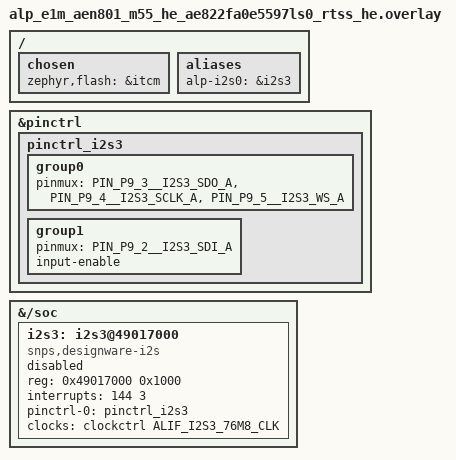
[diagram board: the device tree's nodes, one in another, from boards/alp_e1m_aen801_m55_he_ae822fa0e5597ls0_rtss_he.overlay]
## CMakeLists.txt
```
# SPDX-License-Identifier: Apache-2.0
cmake_minimum_required(VERSION 3.20)
find_package(Zephyr REQUIRED HINTS $ENV{ZEPHYR_BASE})
project(aen_i2s_amp_alif LANGUAGES C)
target_sources(app PRIVATE src/main.c)
```

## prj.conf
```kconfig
# SPDX-License-Identifier: Apache-2.0
#
# Bench RAM-run config for the E1M-AEN801 (M55-HE).

# Tier-1.5 / Tier-2 driver Kconfigs (incl. CONFIG_I2S_DW) are gated under ALP_SDK.
CONFIG_ALP_SDK=y

# I2S subsystem + the vendored Alif DesignWare I2S driver. CONFIG_I2S_DW is
# `default y` once the i2s0 node is enabled (DT_HAS_SNPS_DESIGNWARE_I2S_ENABLED)
# and it `select`s PINCTRL itself -- we only turn on the I2S API here.
CONFIG_I2S=y

# Tone blocks come from a k_mem_slab + the kernel heap.
CONFIG_HEAP_MEM_POOL_SIZE=16384
CONFIG_MAIN_STACK_SIZE=4096

# FIFO is fed by the CPU from a plain buffer -- keep the data path coherent on
# this M55 bench by disabling the D-cache (matches the other E8 bench apps).
CONFIG_DCACHE=n

# Console: Alp UART console -- E1M edge UART0 (Alif UART5, P3_4/P3_5, 115200
# 8N1, NS16550), the E1M-AEN801 carrier console. The board _defconfig already
# selects it; we set it explicitly here so the example is self-describing.
CONFIG_SERIAL=y
CONFIG_CONSOLE=y
CONFIG_UART_CONSOLE=y
CONFIG_UART_INTERRUPT_DRIVEN=y
# Serial-less bench? Comment the four lines above and uncomment these to read
# 'ram_console_buf' over SWD instead:
# CONFIG_RAM_CONSOLE=y
# CONFIG_RAM_CONSOLE_BUFFER_SIZE=2048
# CONFIG_UART_CONSOLE=n
CONFIG_PRINTK=y
```

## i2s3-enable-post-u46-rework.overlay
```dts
/*
 * Copyright (c) 2026 Alp Lab AB
 * SPDX-License-Identifier: Apache-2.0
 *
 * The single documented switch that turns i2s3 back on -- see the SAFETY
 * note in boards/alp_e1m_aen801_m55_he_ae822fa0e5597ls0_rtss_he.overlay for
 * why the node ships "disabled" by default on EVK rev 2626-R2 (U46 has no
 * Hi-Z state, and I2S0_SDO/SCLK/WS on P9_3/4/5 run through it backwards).
 *
 * Apply ONLY once U46 is a 3257-type bus switch -- removes the
 * contention hazard regardless of which rail powers it; this app
 * never drives EN or SEL and does not test the amps. Amp audibility
 * is separate: on E1M-AEN803 serial 2026W36-0002 (2026-09-15), VCC was moved to +3V3
 * between a silent run and an audible run, not established as the
 * only difference; a switch rated for 1.8 V VCC is the untested
 * alternative (see include/alp/boards/alp_e1m_evk.h's I2S mux block):
 *
 *   west build -b alp_e1m_aen801_m55_he/ae822fa0e5597ls0/rtss_he \
 *       examples/aen/aen-i2s-amp-alif -- \
 *       -DEXTRA_DTC_OVERLAY_FILE=i2s3-enable-post-u46-rework.overlay
 *   (relative to this app's own source dir, examples/aen/aen-i2s-amp-alif)
 */

&i2s3 {
	status = "okay";
};
```

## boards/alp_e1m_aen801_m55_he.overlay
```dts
/*
 * Copyright (c) 2026 Alp Lab AB
 * SPDX-License-Identifier: Apache-2.0
 *
 * I2S0 audio-out overlay for the E1M-AEN801 (E8, M55-HE).
 *
 * i2s0@49014000 (compatible snps,designware-i2s, IRQ 141, clock ALIF_I2S0_76M8_CLK)
 * is transcribed from the Apache-2.0 zephyr_alif fork (dts/arm/alif/ensemble/
 * common/e1.dtsi) -- the alp-sdk E8 SoC dtsi doesn't carry it, so it is enabled
 * here.  Driver: drivers/i2s/i2s_dw.c (vendored Tier-2, CONFIG_I2S_DW).
 *
 * PADS -- TBD, see [[project_pending_hw_configs]] / [[project_som_pad_map_lives_in_alp_sdk]]:
 * the SoC offers I2S0 on TWO pad options (header ensemble-e4-e6-e8-pinctrl.h):
 *   A: P1_6 SDI / P1_7 SDO / P3_0 SCLK / P3_1 WS
 *   B: P4_1 SDI / P4_2 SDO / P4_3 SCLK / P4_4 WS
 * Which one the E1M-AEN801 SoM routes to the I2S0 edge (and on to the EVK 74LVC157
 * mux -> TAS2563 amps) is NOT yet declared in metadata/e1m_modules/E1M-AEN801.yaml.
 * This overlay uses the **A** option as a documented default; CONFIRM against the
 * SoM schematic before trusting amp output.  Re-point to the B group if the SoM
 * routes I2S0_B.
 */
#include <zephyr/dt-bindings/pinctrl/alif-ensemble-pinctrl.h>
#include <zephyr/dt-bindings/clock/alif-ensemble-clocks-ext.h>

/ {
	chosen {
		zephyr,flash = &itcm; /* bench RAM/SES-load; path-ref form */
		/delete-property/ zephyr,code-partition;
	};
	aliases {
		alp-i2s0 = &i2s0;
	};
};

&pinctrl {
	pinctrl_i2s0: pinctrl_i2s0 {
		/* TX path: SDO (data out) + SCLK + WS.  (read-enable, which the fork
		 * sets on the SDI input pad, is not in the upstream alif,pinctrl
		 * binding -- REN-off is the upstream default and SDI is unused for TX.) */
		group0 {
			pinmux = <PIN_P1_7__I2S0_SDO_A>, <PIN_P3_0__I2S0_SCLK_A>,
				 <PIN_P3_1__I2S0_WS_A>;
		};
	};
};

&{/soc} {
	i2s0: i2s0@49014000 {
		compatible = "snps,designware-i2s";
		reg = <0x49014000 0x1000>;
		interrupts = <141 3>;
		pinctrl-0 = <&pinctrl_i2s0>;
		pinctrl-names = "default";
		clocks = <&clockctrl ALIF_I2S0_76M8_CLK>;
		status = "okay";
	};
};
```

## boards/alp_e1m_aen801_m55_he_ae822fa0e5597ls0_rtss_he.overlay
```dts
/*
 * Copyright (c) 2026 Alp Lab AB
 * SPDX-License-Identifier: Apache-2.0
 *
 * Audio-I2S out overlay for the E1M-AEN801 (E8, M55-HE).
 *
 * The EVK audio I2S is the SoC's **i2s3** (i2s3@49017000) -- per the AUTHORITATIVE
 * SoM pinout metadata/e1m_modules/aen/from-alif.tsv, the board's "I2S0_*" audio
 * signals are wired to I2S3_*_A on P9_2..P9_5:
 *   I2S0_SDI -> I2S3_SDI_A = P9_2 | I2S0_SDO -> I2S3_SDO_A = P9_3
 *   I2S0_SCLK -> I2S3_SCLK_A = P9_4 | I2S0_WS -> I2S3_WS_A = P9_5
 * (NOT i2s0@49014000 -- that was the first cut's wrong instance.) The
 * snps,designware-i2s node + driver (drivers/i2s/i2s_dw.c, CONFIG_I2S_DW) are
 * transcribed from the fork; alias alp-i2s0 -> &i2s3 keeps the portable bus id.
 *
 * DISABLED BY DEFAULT on EVK rev 2626-R2: I2S0_SDO/SCLK/WS (P9_3/4/5) run
 * through U46, a 74LVC157 2:1 mux with NO high-impedance state -- with /E
 * high its Y outputs are forced LOW, not floated. Those Y outputs are wired
 * BACKWARDS for this direction (they drive the SoC's own I2S0_* pads, not
 * the amps or the M.2 slot), so the instant this i2s3 node's pinctrl muxes
 * P9_3/4/5 to the I2S3 alternate function and the controller drives them,
 * the SoC fights U46's forced-low outputs on the same pads -- whether or
 * not U46's /E is ever asserted. Disabling the whole node, not just
 * skipping the app's i2s_configure()/i2s_write() calls, is the point: a
 * disabled node gets no pinctrl-0 applied and no clock enabled at driver
 * init, so nothing drives P9_3/4/5 at all. To exercise this node once U46
 * is a 3257-type bus switch (removes this contention regardless of which
 * rail powers it -- this app never drives EN or SEL and does not test
 * the amps; amp audibility is a separate, stricter condition -- VCC was
 * moved to +3V3 between a silent run and an audible run on
 * E1M-AEN803 serial 2026W36-0002, not established as the only difference -- see
 * include/alp/boards/alp_e1m_evk.h's I2S mux block):
 * `-DEXTRA_DTC_OVERLAY_FILE=i2s3-enable-post-u46-rework.overlay`
 * (resolved relative to this app's own source dir, examples/aen/aen-i2s-amp-alif;
 * that file just sets `&i2s3 { status = "okay"; };`) -- the single documented
 * switch; nothing else in this app needs to change.
 */
#include <zephyr/dt-bindings/pinctrl/alif-ensemble-pinctrl.h>
#include <zephyr/dt-bindings/clock/alif-ensemble-clocks-ext.h>

/ {
	chosen {
		zephyr,flash = &itcm; /* bench RAM/SES-load; path-ref form */
		/delete-property/ zephyr,code-partition;
	};
	aliases {
		alp-i2s0 = &i2s3;
	};
};

&pinctrl {
	pinctrl_i2s3: pinctrl_i2s3 {
		/* TX: SDO + SCLK + WS, the I2S3_*_A route (P9_3/4/5). RX: SDI
		 * (P9_2, I2S3_SDI_A) -- U46's 4Y is the one leg of that mux wired
		 * the correct direction (unlike SDO/SCLK/WS, which contend with
		 * the SoC and are why this node ships disabled -- see the
		 * file-header SAFETY note), feeding the amps' SDOUT/IV-sense back
		 * to the SoC. input-enable sets the pad's REN bit so the input
		 * buffer actually samples; without it the mux alone is not
		 * sufficient to receive (REN defaults off). The original TX-only
		 * scope here was a deliberate choice, not a hazard -- that scope
		 * has since widened. Still inert on its own: this node ships
		 * "disabled" by default, so pinctrl-0 is not applied until
		 * i2s3-enable-post-u46-rework.overlay flips it "okay". */
		group0 {
			pinmux = <PIN_P9_3__I2S3_SDO_A>, <PIN_P9_4__I2S3_SCLK_A>,
				 <PIN_P9_5__I2S3_WS_A>;
		};
		group1 {
			pinmux = <PIN_P9_2__I2S3_SDI_A>;
			input-enable;
		};
	};
};

&{/soc} {
	i2s3: i2s3@49017000 {
		compatible = "snps,designware-i2s";
		reg = <0x49017000 0x1000>;
		interrupts = <144 3>;
		pinctrl-0 = <&pinctrl_i2s3>;
		pinctrl-names = "default";
		clocks = <&clockctrl ALIF_I2S3_76M8_CLK>;
		/* "disabled" by default -- see the file-header SAFETY note above.
		 * -DEXTRA_DTC_OVERLAY_FILE=i2s3-enable-post-u46-rework.overlay
		 * flips this back to "okay" once U46 is a 3257-type bus
		 * switch (any rail -- see the file-header note). */
		status = "disabled";
	};
};
```

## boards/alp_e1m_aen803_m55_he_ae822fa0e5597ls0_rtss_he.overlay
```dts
/*
 * Copyright (c) 2026 Alp Lab AB
 * SPDX-License-Identifier: Apache-2.0
 *
 * Audio-I2S out overlay for the E1M-AEN803 (E8, M55-HE).
 *
 * The EVK audio I2S is the SoC's **i2s3** (i2s3@49017000) -- per the AUTHORITATIVE
 * SoM pinout metadata/e1m_modules/aen/from-alif.tsv, the board's "I2S0_*" audio
 * signals are wired to I2S3_*_A on P9_2..P9_5:
 *   I2S0_SDI -> I2S3_SDI_A = P9_2 | I2S0_SDO -> I2S3_SDO_A = P9_3
 *   I2S0_SCLK -> I2S3_SCLK_A = P9_4 | I2S0_WS -> I2S3_WS_A = P9_5
 * (NOT i2s0@49014000 -- that was the first cut's wrong instance.) The
 * snps,designware-i2s node + driver (drivers/i2s/i2s_dw.c, CONFIG_I2S_DW) are
 * transcribed from the fork; alias alp-i2s0 -> &i2s3 keeps the portable bus id.
 *
 * DISABLED BY DEFAULT on EVK rev 2626-R2: I2S0_SDO/SCLK/WS (P9_3/4/5) run
 * through U46, a 74LVC157 2:1 mux with NO high-impedance state -- with /E
 * high its Y outputs are forced LOW, not floated. Those Y outputs are wired
 * BACKWARDS for this direction (they drive the SoC's own I2S0_* pads, not
 * the amps or the M.2 slot), so the instant this i2s3 node's pinctrl muxes
 * P9_3/4/5 to the I2S3 alternate function and the controller drives them,
 * the SoC fights U46's forced-low outputs on the same pads -- whether or
 * not U46's /E is ever asserted. Disabling the whole node, not just
 * skipping the app's i2s_configure()/i2s_write() calls, is the point: a
 * disabled node gets no pinctrl-0 applied and no clock enabled at driver
 * init, so nothing drives P9_3/4/5 at all. To exercise this node once U46
 * is a 3257-type bus switch (removes this contention regardless of which
 * rail powers it -- this app never drives EN or SEL and does not test
 * the amps; amp audibility is a separate, stricter condition -- VCC was
 * moved to +3V3 between a silent run and an audible run on
 * E1M-AEN803 serial 2026W36-0002, not established as the only difference -- see
 * include/alp/boards/alp_e1m_evk.h's I2S mux block):
 * `-DEXTRA_DTC_OVERLAY_FILE=i2s3-enable-post-u46-rework.overlay`
 * (resolved relative to this app's own source dir, examples/aen/aen-i2s-amp-alif;
 * that file just sets `&i2s3 { status = "okay"; };`) -- the single documented
 * switch; nothing else in this app needs to change.
 */
#include <zephyr/dt-bindings/pinctrl/alif-ensemble-pinctrl.h>
#include <zephyr/dt-bindings/clock/alif-ensemble-clocks-ext.h>

/ {
	chosen {
		zephyr,flash = &itcm; /* bench RAM/SES-load; path-ref form */
		/delete-property/ zephyr,code-partition;
	};
	aliases {
		alp-i2s0 = &i2s3;
	};
};

&pinctrl {
	pinctrl_i2s3: pinctrl_i2s3 {
		/* TX: SDO + SCLK + WS, the I2S3_*_A route (P9_3/4/5). RX: SDI
		 * (P9_2, I2S3_SDI_A) -- U46's 4Y is the one leg of that mux wired
		 * the correct direction (unlike SDO/SCLK/WS, which contend with
		 * the SoC and are why this node ships disabled -- see the
		 * file-header SAFETY note), feeding the amps' SDOUT/IV-sense back
		 * to the SoC. input-enable sets the pad's REN bit so the input
		 * buffer actually samples; without it the mux alone is not
		 * sufficient to receive (REN defaults off). The original TX-only
		 * scope here was a deliberate choice, not a hazard -- that scope
		 * has since widened. Still inert on its own: this node ships
		 * "disabled" by default, so pinctrl-0 is not applied until
		 * i2s3-enable-post-u46-rework.overlay flips it "okay". */
		group0 {
			pinmux = <PIN_P9_3__I2S3_SDO_A>, <PIN_P9_4__I2S3_SCLK_A>,
				 <PIN_P9_5__I2S3_WS_A>;
		};
		group1 {
			pinmux = <PIN_P9_2__I2S3_SDI_A>;
			input-enable;
		};
	};
};

&{/soc} {
	i2s3: i2s3@49017000 {
		compatible = "snps,designware-i2s";
		reg = <0x49017000 0x1000>;
		interrupts = <144 3>;
		pinctrl-0 = <&pinctrl_i2s3>;
		pinctrl-names = "default";
		clocks = <&clockctrl ALIF_I2S3_76M8_CLK>;
		/* "disabled" by default -- see the file-header SAFETY note above.
		 * -DEXTRA_DTC_OVERLAY_FILE=i2s3-enable-post-u46-rework.overlay
		 * flips this back to "okay" once U46 is a 3257-type bus
		 * switch (any rail -- see the file-header note). */
		status = "disabled";
	};
};
```

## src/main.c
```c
/*
 * Copyright (c) 2026 Alp Lab AB
 * SPDX-License-Identifier: Apache-2.0
 *
 * aen-i2s-amp-alif -- drive a tone out of the Ensemble E8 audio I2S (the SoC's
 * i2s3@49017000) via the vendored snps,designware-i2s driver (drivers/i2s/i2s_dw.c),
 * on the E1M-AEN801 (M55-HE).  Uses the standard Zephyr I2S API (i2s_configure /
 * i2s_write / i2s_trigger) on DT_ALIAS(alp_i2s0) = &i2s3 (the SoM "I2S0_*" audio
 * signals route to I2S3_*_A on P9_3/4/5 -- per metadata from-alif.tsv).
 *
 * The 76.8 MHz audio reference (CGU master) and the I2S bit-clock divider are now
 * programmed by the Tier-1.5 clockctrl west-patch
 * (zephyr/patches/zephyr/0001-clock_control_alif-master-source-expmst-i2s-setrate.patch),
 * NOT by this example: i2s_configure() -> the i2s_dw driver calls
 * clock_control_on()/clock_control_set_rate(), and the patched clockctrl enables
 * the CGU master source and divides it down to SCLK (the same master-source fix
 * that made the PDM mics capture).  The controller then clocks a tone out on
 * SCLK/WS/SDO.  On the EVK that signal reaches the two TAS2563
 * smart-amplifiers through a 2:1 mux (U46): SELECT = CC3501E GPIO13 (over the
 * inter-chip SPI bridge, currently firmware-gated), both hw revisions; ENABLE
 * is REVISION-DEPENDENT -- Alif P7.1 (direct GPIO) on r1, CC3501E GPIO_30 on
 * r2 -- see include/alp/boards/alp_e1m_evk.h's I2S mux block.  AUDIBLE amp
 * output additionally needs U46 to be a 3257-type bus switch with VCC on
 * +3V3, OR a switch rated for 1.8 V VCC (untested)
 * (on a bench E1M-AEN803, VCC was moved to +3V3 between a silent run and
 * an audible run, not established as the only difference; the as-built
 * 74LVC157 can never pass this direction regardless, see the same header)
 * + the mux routed + the TAS2563 configured; this example validates only
 * the I2S controller + clock path.
 *
 * PASS gate: device ready, i2s_configure + i2s_write(s) + i2s_trigger(START) all
 * return 0 and the TX FIFO DRAINs cleanly with the 76.8 MHz clock ON (the
 * controller genuinely clocked the tone out).  A run that cannot drain is PARTIAL.
 */

#include <stdio.h>
#include <stdint.h>
#include <string.h>

#include <zephyr/kernel.h>
#include <zephyr/device.h>
#include <zephyr/drivers/i2s.h>

#define I2S_NODE DT_ALIAS(alp_i2s0)
/* i2s3 ships "disabled" by default on EVK rev 2626-R2 -- see the SAFETY
 * note in boards/alp_e1m_aen801_m55_he_ae822fa0e5597ls0_rtss_he.overlay.
 * DEVICE_DT_GET() on a disabled node fails to LINK, not just to run, so
 * this has to be a compile-time branch: with the node disabled (the
 * default), i2s_dev() returns NULL and main() prints why and exits
 * before touching the Zephyr I2S API at all. */
#if DT_NODE_HAS_STATUS(I2S_NODE, okay)
static const struct device *i2s_dev(void)
{
	return DEVICE_DT_GET(I2S_NODE);
}
#else
static const struct device *i2s_dev(void)
{
	return NULL;
}
#endif
#define SAMPLE_RATE_HZ 48000
#define WORD_BITS      16
#define NUM_CHANNELS   2 /* stereo: L/R interleaved */
#define BLOCK_FRAMES   256u
#define BLOCK_BYTES    (BLOCK_FRAMES * NUM_CHANNELS * (WORD_BITS / 8u))
/* BLOCK_COUNT sizes the slab bigger than what's actually queued
 * (BLOCKS_TO_SEND) so the driver always has a free block on hand even while
 * the app is still allocating/filling the next one -- avoids an alloc stall
 * mid-fill. */
#define BLOCK_COUNT    8u
#define BLOCKS_TO_SEND 4u
#define TX_TIMEOUT_MS  1000

K_MEM_SLAB_DEFINE_STATIC(i2s_slab, BLOCK_BYTES, BLOCK_COUNT, 4);

/* Triangle wave (no libm): a full +/- ramp across the block, written to both
 * channels.  Audible on a real codec; deterministic on every toolchain. */
static void fill_triangle(int16_t *frames)
{
	const int16_t step = (int16_t)(0x7FFF / (BLOCK_FRAMES / 2u));
	int16_t       v    = 0;
	int           dir  = 1;

	for (unsigned f = 0; f < BLOCK_FRAMES; f++) {
		frames[2u * f]      = v; /* left  */
		frames[2u * f + 1u] = v; /* right */
		if (dir > 0 && v > (int16_t)(0x7FFF - step)) {
			dir = -1;
		} else if (dir < 0 && v < (int16_t)(-0x7FFF + step)) {
			dir = 1;
		}
		v = (int16_t)(v + dir * step);
	}
}

int main(void)
{
	const struct device *i2s = i2s_dev();

	if (i2s == NULL) {
		printf("[i2s] SOUND: playback skipped -- EVK 2626-R2 U46 has no Hi-Z state and "
		       "routes SoC I2S outputs into mux outputs (a working, audible mux "
		       "requires U46 to be a 3257-type switch powered from +3V3, or a "
		       "1.8 V-rated switch (untested); see alp_e1m_evk.h); i2s3 is left "
		       "\"disabled\" in the "
		       "board overlay so no pinctrl is applied and no clock is emitted\n"
		       "[i2s] RESULT SKIPPED: i2s3 disabled by default on this "
		       "board revision\n[i2s] done\n");
		return 0;
	}

	printf("[i2s] open %s (audio I2S = i2s3, %d ch @ %d Hz, %d-bit TX)\n",
	       i2s->name,
	       NUM_CHANNELS,
	       SAMPLE_RATE_HZ,
	       WORD_BITS);
	if (!device_is_ready(i2s)) {
		printf("[i2s] RESULT FAIL: device not ready\n[i2s] done\n");
		return 0;
	}

	struct i2s_config cfg = {
		.word_size = WORD_BITS,
		.channels  = NUM_CHANNELS,
		.format    = I2S_FMT_DATA_FORMAT_I2S,
		/* Both CONTROLLER flags: the i2s3 controller itself generates WS
		 * (frame clock) and SCLK (bit clock) from the 76.8 MHz audio
		 * source, rather than expecting an external codec to drive them --
		 * matches the EVK wiring, where i2s3 is the only clock source on
		 * the SCLK/WS/SDO net. */
		.options        = I2S_OPT_FRAME_CLK_CONTROLLER | I2S_OPT_BIT_CLK_CONTROLLER,
		.frame_clk_freq = SAMPLE_RATE_HZ,
		.mem_slab       = &i2s_slab,
		.block_size     = BLOCK_BYTES,
		.timeout        = TX_TIMEOUT_MS,
	};

	/* No raw clock poke here: the patched Tier-1.5 clockctrl enables the CGU
	 * master 76.8 MHz source and programs the I2Sx_CTRL bit-clock divider inside
	 * i2s_configure() (via clock_control_on()/set_rate()). */
	int rc = i2s_configure(i2s, I2S_DIR_TX, &cfg);
	printf("[i2s] i2s_configure(TX) -> %d\n", rc);
	if (rc != 0) {
		printf("[i2s] RESULT FAIL: configure rc=%d\n[i2s] done\n", rc);
		return 0;
	}

	/* Queue the tone blocks BEFORE START so the FIFO never underruns. */
	unsigned queued = 0;
	for (unsigned b = 0; b < BLOCKS_TO_SEND; b++) {
		void *block = NULL;
		if (k_mem_slab_alloc(&i2s_slab, &block, K_MSEC(TX_TIMEOUT_MS)) != 0) {
			printf("[i2s] slab alloc failed at block %u\n", b);
			break;
		}
		fill_triangle((int16_t *)block);
		rc = i2s_write(i2s, block, BLOCK_BYTES);
		if (rc != 0) {
			printf("[i2s] i2s_write[%u] -> %d\n", b, rc);
			k_mem_slab_free(&i2s_slab, block);
			break;
		}
		queued++;
	}
	printf("[i2s] queued %u/%u tone blocks\n", queued, BLOCKS_TO_SEND);

	rc = i2s_trigger(i2s, I2S_DIR_TX, I2S_TRIGGER_START);
	printf("[i2s] i2s_trigger(START) -> %d\n", rc);
	if (rc != 0) {
		printf("[i2s] RESULT FAIL: start rc=%d\n[i2s] done\n", rc);
		return 0;
	}

	/* Wait for the ISR to actually clock every queued block out BEFORE asking
	 * the driver to DRAIN: the i2s_dw DRAIN tears the TX channel/clock down
	 * rather than blocking, so triggering it immediately would stop the
	 * controller before the tone was transmitted and the PASS gate would never
	 * observe a real drain.  A block is returned to the slab only once the ISR
	 * has finished sending it, so num_free climbs back to BLOCK_COUNT exactly
	 * when the last queued block has been clocked out. */
	bool consumed = false;
	for (int waited_ms = 0; waited_ms <= TX_TIMEOUT_MS; waited_ms += 10) {
		if (k_mem_slab_num_free_get(&i2s_slab) == BLOCK_COUNT) {
			consumed = true;
			break;
		}
		k_msleep(10);
	}
	printf("[i2s] TX blocks clocked out: %s (slab free %u/%u)\n",
	       consumed ? "yes" : "TIMEOUT",
	       k_mem_slab_num_free_get(&i2s_slab),
	       BLOCK_COUNT);

	/* Now every block is on the wire; DRAIN just flushes the (empty) FIFO and
	 * stops the TX channel cleanly. */
	rc = i2s_trigger(i2s, I2S_DIR_TX, I2S_TRIGGER_DRAIN);
	printf("[i2s] i2s_trigger(DRAIN) -> %d\n", rc);

	bool drained = (rc == 0) && consumed && (queued == BLOCKS_TO_SEND);
	printf("[i2s] RESULT %s: %s\n",
	       drained ? "PASS" : "PARTIAL",
	       drained ? "i2s3 TX clocked the tone out with the 76.8MHz audio clock ON (SCLK/WS/SDO "
	                 "on P9_3/4/5). For AUDIBLE amp out: U46 needs a 3257-type switch on +3V3, "
	                 "OR a switch rated for 1.8V VCC (untested) "
	                 "(not the stock 74LVC157), routed + the TAS2563 configured (ACTIVE)"
	               : "configured but TX did not drain cleanly (check clock/pinctrl)");
	printf("[i2s] done\n");
	return 0;
}
```
